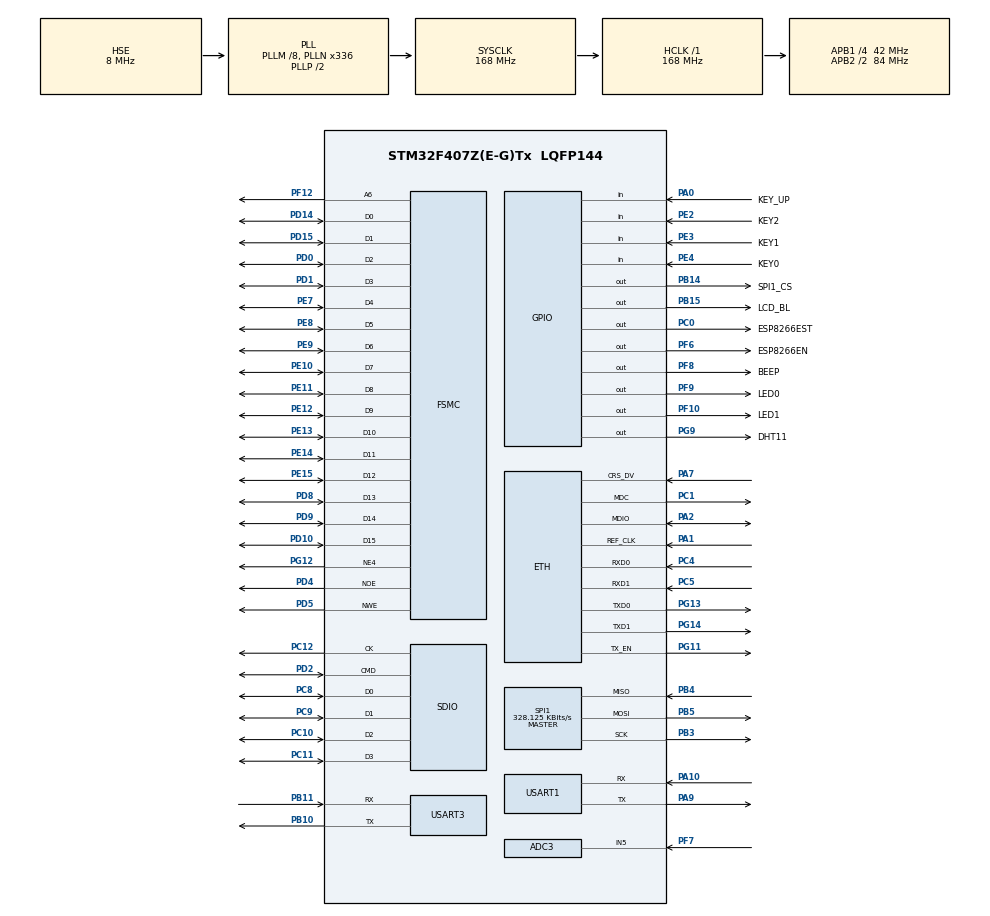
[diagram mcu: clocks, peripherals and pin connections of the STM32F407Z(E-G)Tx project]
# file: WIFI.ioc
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ADC3.Channel-6\#ChannelRegularConversion=ADC_CHANNEL_5
ADC3.NbrOfConversionFlag=1
ADC3.Rank-6\#ChannelRegularConversion=1
ADC3.SamplingTime-6\#ChannelRegularConversion=ADC_SAMPLETIME_3CYCLES
Dma.Request0=SDIO_RX
Dma.Request1=SDIO_TX
Dma.SDIO_RX.0.Direction=DMA_PERIPH_TO_MEMORY
Dma.SDIO_RX.0.FIFOMode=DMA_FIFOMODE_ENABLE
Dma.SDIO_RX.0.FIFOThreshold=DMA_FIFO_THRESHOLD_FULL
Dma.SDIO_RX.0.Instance=DMA2_Stream3
Dma.SDIO_RX.0.MemBurst=DMA_MBURST_INC4
Dma.SDIO_RX.0.MemDataAlignment=DMA_MDATAALIGN_WORD
Dma.SDIO_RX.0.MemInc=DMA_MINC_ENABLE
Dma.SDIO_RX.0.Mode=DMA_PFCTRL
Dma.SDIO_RX.0.PeriphBurst=DMA_PBURST_INC4
Dma.SDIO_RX.0.PeriphDataAlignment=DMA_PDATAALIGN_WORD
Dma.SDIO_RX.0.PeriphInc=DMA_PINC_DISABLE
Dma.SDIO_RX.0.Priority=DMA_PRIORITY_HIGH
Dma.SDIO_TX.1.Direction=DMA_MEMORY_TO_PERIPH
Dma.SDIO_TX.1.FIFOMode=DMA_FIFOMODE_ENABLE
Dma.SDIO_TX.1.FIFOThreshold=DMA_FIFO_THRESHOLD_FULL
Dma.SDIO_TX.1.Instance=DMA2_Stream6
Dma.SDIO_TX.1.MemBurst=DMA_MBURST_INC4
Dma.SDIO_TX.1.MemDataAlignment=DMA_MDATAALIGN_WORD
Dma.SDIO_TX.1.MemInc=DMA_MINC_ENABLE
Dma.SDIO_TX.1.Mode=DMA_PFCTRL
Dma.SDIO_TX.1.PeriphBurst=DMA_PBURST_INC4
Dma.SDIO_TX.1.PeriphDataAlignment=DMA_PDATAALIGN_WORD
Dma.SDIO_TX.1.PeriphInc=DMA_PINC_DISABLE
Dma.SDIO_TX.1.Priority=DMA_PRIORITY_HIGH
ETH.MediaInterface=HAL_ETH_RMII_MODE
FATFS.BSP.number=1
FATFS.USE_DMA_CODE_SD=1
FATFS._CODE_PAGE=936
FATFS._USE_LFN=2
FATFS0.BSP.STBoard=false
FATFS0.BSP.api=Unknown
FATFS0.BSP.instance=PA0-WKUP
FATFS0.BSP.ip=GPIO
FATFS0.BSP.mode=Input
FATFS0.BSP.name=Detect_SDIO
FATFS0.BSP.solution=PA0-WKUP
FSMC.AddressSetupTime1=8
FSMC.BusTurnAroundDuration1=0
FSMC.DataSetupTime1=15
FSMC.ExtendedDataSetupTime1=15
FSMC.ExtendedMode1=FSMC_EXTENDED_MODE_ENABLE
LWIP.BSP.number=1
LWIP.GATEWAY_ADDRESS=192.168.010.001
LWIP.IP_ADDRESS=192.168.010.123
LWIP.LWIP_DHCP=0
LWIP.LWIP_DNS=0
LWIP.NETMASK_ADDRESS=255.255.255.000
LWIP.Version=v2.1.2_Cube
LWIP0.BSP.STBoard=false
LWIP0.BSP.api=BSP_COMPONENT_DRIVER
LWIP0.BSP.component=LAN8742
LWIP0.BSP.instance=LAN8742
LWIP0.BSP.name=Driver_PHY
LWIP0.BSP.semaphore=S_LAN8742
LWIP0.BSP.solution=LAN8742
Mcu.Family=STM32F4
Mcu.Name=STM32F407Z(E-G)Tx
Mcu.Package=LQFP144
NVIC.DMA2_Stream3_IRQn=true\:1\:0\:true\:false\:true\:false\:true\:true
NVIC.DMA2_Stream6_IRQn=true\:1\:0\:true\:false\:true\:false\:true\:true
NVIC.ETH_IRQn=true\:3\:0\:true\:false\:true\:true\:true\:true
NVIC.ETH_WKUP_IRQn=true\:3\:0\:true\:false\:true\:true\:true\:true
NVIC.PriorityGroup=NVIC_PRIORITYGROUP_4
NVIC.SDIO_IRQn=true\:1\:0\:true\:false\:true\:true\:true\:true
NVIC.USART1_IRQn=true\:4\:0\:true\:false\:true\:true\:true\:true
NVIC.USART3_IRQn=true\:0\:0\:false\:false\:true\:true\:true\:true
PA0-WKUP.GPIO_Label=KEY_UP
PA0-WKUP.GPIO_PuPd=GPIO_PULLDOWN
PA0-WKUP.Signal=GPIO_Input
PA1.Mode=RMII
PA1.Signal=ETH_REF_CLK
PA10.Mode=Asynchronous
PA10.Signal=USART1_RX
PA13.Mode=Serial_Wire
PA13.Signal=SYS_JTMS-SWDIO
PA14.Mode=Serial_Wire
PA14.Signal=SYS_JTCK-SWCLK
PA2.Mode=RMII
PA2.Signal=ETH_MDIO
PA7.Mode=RMII
PA7.Signal=ETH_CRS_DV
PA9.Mode=Asynchronous
PA9.Signal=USART1_TX
PB10.Mode=Asynchronous
PB10.Signal=USART3_TX
PB11.Mode=Asynchronous
PB11.Signal=USART3_RX
PB14.GPIO_Label=SPI1_CS
PB14.GPIO_ModeDefaultOutputPP=GPIO_MODE_OUTPUT_PP
PB14.GPIO_Speed=GPIO_SPEED_FREQ_HIGH
PB14.PinState=GPIO_PIN_SET
PB14.Signal=GPIO_Output
PB15.GPIO_Label=LCD_BL
PB15.GPIO_Speed=GPIO_SPEED_FREQ_VERY_HIGH
PB15.PinState=GPIO_PIN_SET
PB15.Signal=GPIO_Output
PB3.Mode=Full_Duplex_Master
PB3.Signal=SPI1_SCK
PB4.Mode=Full_Duplex_Master
PB4.Signal=SPI1_MISO
PB5.Mode=Full_Duplex_Master
PB5.Signal=SPI1_MOSI
PC0.GPIO_Label=ESP8266EST
PC0.Signal=GPIO_Output
PC1.Mode=RMII
PC1.Signal=ETH_MDC
PC10.Mode=SD_4_bits_Wide_bus
PC10.Signal=SDIO_D2
PC11.Mode=SD_4_bits_Wide_bus
PC11.Signal=SDIO_D3
PC12.Mode=SD_4_bits_Wide_bus
PC12.Signal=SDIO_CK
PC14-OSC32_IN.Mode=LSE-External-Oscillator
PC14-OSC32_IN.Signal=RCC_OSC32_IN
PC15-OSC32_OUT.Mode=LSE-External-Oscillator
PC15-OSC32_OUT.Signal=RCC_OSC32_OUT
PC4.Mode=RMII
PC4.Signal=ETH_RXD0
PC5.Mode=RMII
PC5.Signal=ETH_RXD1
PC8.Mode=SD_4_bits_Wide_bus
PC8.Signal=SDIO_D0
PC9.Mode=SD_4_bits_Wide_bus
PC9.Signal=SDIO_D1
PD0.GPIO_PuPd=GPIO_NOPULL
PD0.Signal=FSMC_D2_DA2
PD1.GPIO_PuPd=GPIO_NOPULL
PD1.Signal=FSMC_D3_DA3
PD10.GPIO_PuPd=GPIO_NOPULL
PD10.Signal=FSMC_D15_DA15
PD14.GPIO_PuPd=GPIO_NOPULL
PD14.Signal=FSMC_D0_DA0
PD15.GPIO_PuPd=GPIO_NOPULL
PD15.Signal=FSMC_D1_DA1
PD2.Mode=SD_4_bits_Wide_bus
PD2.Signal=SDIO_CMD
PD4.GPIO_PuPd=GPIO_NOPULL
PD4.Signal=FSMC_NOE
PD5.GPIO_PuPd=GPIO_NOPULL
PD5.Signal=FSMC_NWE
PD8.GPIO_PuPd=GPIO_NOPULL
PD8.Signal=FSMC_D13_DA13
PD9.GPIO_PuPd=GPIO_NOPULL
PD9.Signal=FSMC_D14_DA14
PE10.GPIO_PuPd=GPIO_NOPULL
PE10.Signal=FSMC_D7_DA7
PE11.GPIO_PuPd=GPIO_NOPULL
PE11.Signal=FSMC_D8_DA8
PE12.GPIO_PuPd=GPIO_NOPULL
PE12.Signal=FSMC_D9_DA9
PE13.GPIO_PuPd=GPIO_NOPULL
PE13.Signal=FSMC_D10_DA10
PE14.GPIO_PuPd=GPIO_NOPULL
PE14.Signal=FSMC_D11_DA11
PE15.GPIO_PuPd=GPIO_NOPULL
PE15.Signal=FSMC_D12_DA12
PE2.GPIO_Label=KEY2
PE2.GPIO_PuPd=GPIO_PULLUP
PE2.Signal=GPIO_Input
PE3.GPIO_Label=KEY1
PE3.GPIO_PuPd=GPIO_PULLUP
PE3.Signal=GPIO_Input
PE4.GPIO_Label=KEY0
PE4.GPIO_PuPd=GPIO_PULLUP
PE4.Signal=GPIO_Input
PE7.GPIO_PuPd=GPIO_NOPULL
PE7.Signal=FSMC_D4_DA4
PE8.GPIO_PuPd=GPIO_NOPULL
PE8.Signal=FSMC_D5_DA5
PE9.GPIO_PuPd=GPIO_NOPULL
PE9.Signal=FSMC_D6_DA6
PF10.GPIO_Label=LED1
PF10.GPIO_PuPd=GPIO_PULLUP
PF10.GPIO_Speed=GPIO_SPEED_FREQ_MEDIUM
PF10.Signal=GPIO_Output
PF12.GPIO_PuPd=GPIO_NOPULL
PF12.Signal=FSMC_A6
PF6.GPIO_Label=ESP8266EN
PF6.GPIO_PuPd=GPIO_PULLUP
PF6.GPIO_Speed=GPIO_SPEED_FREQ_LOW
PF6.PinState=GPIO_PIN_SET
PF6.Signal=GPIO_Output
PF7.Mode=IN5
PF7.Signal=ADC3_IN5
PF8.GPIO_Label=BEEP
PF8.GPIO_PuPd=GPIO_PULLUP
PF8.GPIO_Speed=GPIO_SPEED_FREQ_HIGH
PF8.PinState=GPIO_PIN_RESET
PF8.Signal=GPIO_Output
PF9.GPIO_Label=LED0
PF9.GPIO_PuPd=GPIO_PULLUP
PF9.GPIO_Speed=GPIO_SPEED_FREQ_MEDIUM
PF9.Signal=GPIO_Output
PG11.Mode=RMII
PG11.Signal=ETH_TX_EN
PG12.GPIO_PuPd=GPIO_NOPULL
PG12.Mode=NorPsramChipSelect4_1
PG12.Signal=FSMC_NE4
PG13.Mode=RMII
PG13.Signal=ETH_TXD0
PG14.Mode=RMII
PG14.Signal=ETH_TXD1
PG9.GPIO_Label=DHT11
PG9.GPIO_PuPd=GPIO_PULLUP
PG9.GPIO_Speed=GPIO_SPEED_FREQ_HIGH
PG9.PinState=GPIO_PIN_SET
PG9.Signal=GPIO_Output
PH0-OSC_IN.Mode=HSE-External-Oscillator
PH0-OSC_IN.Signal=RCC_OSC_IN
PH1-OSC_OUT.Mode=HSE-External-Oscillator
PH1-OSC_OUT.Signal=RCC_OSC_OUT
ProjectManager.HeapSize=0x200
ProjectManager.StackSize=0x400
ProjectManager.TargetToolchain=CMake
RCC.48MHZClocksFreq_Value=48000000
RCC.AHBFreq_Value=168000000
RCC.APB1CLKDivider=RCC_HCLK_DIV4
RCC.APB1Freq_Value=42000000
RCC.APB1TimFreq_Value=84000000
RCC.APB2CLKDivider=RCC_HCLK_DIV2
RCC.APB2Freq_Value=84000000
RCC.APB2TimFreq_Value=168000000
RCC.CortexFreq_Value=168000000
RCC.HCLKFreq_Value=168000000
RCC.HSE_VALUE=8000000
RCC.HSI_VALUE=16000000
RCC.PLLM=8
RCC.PLLN=336
RCC.PLLQ=7
RCC.PLLSourceVirtual=RCC_PLLSOURCE_HSE
RCC.RCC_RTC_Clock_Source=RCC_RTCCLKSOURCE_LSI
RCC.RCC_RTC_Clock_SourceVirtual=RCC_RTCCLKSOURCE_LSE
RCC.SYSCLKFreq_VALUE=168000000
RCC.SYSCLKSource=RCC_SYSCLKSOURCE_PLLCLK
RCC.VCOOutputFreq_Value=336000000
SH.FSMC_A6.0=FSMC_A6,A6_1
SH.FSMC_D0_DA0.0=FSMC_D0,16b-d1
SH.FSMC_D10_DA10.0=FSMC_D10,16b-d1
SH.FSMC_D11_DA11.0=FSMC_D11,16b-d1
SH.FSMC_D12_DA12.0=FSMC_D12,16b-d1
SH.FSMC_D13_DA13.0=FSMC_D13,16b-d1
SH.FSMC_D14_DA14.0=FSMC_D14,16b-d1
SH.FSMC_D15_DA15.0=FSMC_D15,16b-d1
SH.FSMC_D1_DA1.0=FSMC_D1,16b-d1
SH.FSMC_D2_DA2.0=FSMC_D2,16b-d1
SH.FSMC_D3_DA3.0=FSMC_D3,16b-d1
SH.FSMC_D4_DA4.0=FSMC_D4,16b-d1
SH.FSMC_D5_DA5.0=FSMC_D5,16b-d1
SH.FSMC_D6_DA6.0=FSMC_D6,16b-d1
SH.FSMC_D7_DA7.0=FSMC_D7,16b-d1
SH.FSMC_D8_DA8.0=FSMC_D8,16b-d1
SH.FSMC_D9_DA9.0=FSMC_D9,16b-d1
SH.FSMC_NOE.0=FSMC_NOE,Lcd1
SH.FSMC_NWE.0=FSMC_NWE,Lcd1
SPI1.BaudRatePrescaler=SPI_BAUDRATEPRESCALER_256
SPI1.CLKPhase=SPI_PHASE_1EDGE
SPI1.CLKPolarity=SPI_POLARITY_LOW
SPI1.CalculateBaudRate=328.125 KBits/s
SPI1.Direction=SPI_DIRECTION_2LINES
SPI1.Mode=SPI_MODE_MASTER
SPI1.VirtualType=VM_MASTER
TIM2.AutoReloadPreload=TIM_AUTORELOAD_PRELOAD_ENABLE
TIM2.Prescaler=83
USART1.VirtualMode=VM_ASYNC
USART3.VirtualMode=VM_ASYNC
VP_FATFS_VS_SDIO.Mode=SDIO
VP_LWIP_VS_Enabled.Mode=Enabled
VP_TIM2_VS_ClockSourceINT.Mode=Internal
board=custom

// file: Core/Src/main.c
/* USER CODE BEGIN Header */
/* USER CODE END Header */
#include "main.h"
#include "fatfs.h"
#include "lwip.h"

/* USER CODE BEGIN Includes */
#include "stdio.h"
#include "string.h"
#include "stdbool.h"
#include "../../Library/led/led.h"
#include "../../Library/key/key.h"
#include "../../Library/beep/beep.h"
#include "../../Library/delay/delay.h"
#include "../../Library/tftlcd/tftlcd.h"
#include "../../Library/DHT11/dht11.h"
#include "../../Library/Light_Sensor/light_sensor.h"
#include "../../Library/mpu6050/MPU6050.h"
#include "../../Library/aliyun_iot/aliyun_iot.h"
/* USER CODE END Includes */

ADC_HandleTypeDef hadc3;

SD_HandleTypeDef hsd;
DMA_HandleTypeDef hdma_sdio_rx;
DMA_HandleTypeDef hdma_sdio_tx;

SPI_HandleTypeDef hspi1;

TIM_HandleTypeDef htim2;

UART_HandleTypeDef huart1;
UART_HandleTypeDef huart3;

SRAM_HandleTypeDef hsram1;

/* USER CODE BEGIN PV */
/* 串口/任务状态计数，用于后续调试或界面显示 */
static uint32_t g_uart_test_count = 0U;
/* MPU6050 基础驱动和 DMP 姿态解算模块的初始化状态 */
static uint8_t g_mpu_ready = 0U;
static uint8_t g_mpu_dmp_ready = 0U;
/* 非阻塞刷新定时器：主循环每 500ms 刷新一次传感器数据 */
static delay_nb_timer_t g_sensor_refresh_timer;
/* 光照、温湿度和姿态角的最新采样值，会同步给 LCD 和阿里云物联网模块 */
static uint16_t g_light_adc_value = 0U;
static float g_light_voltage_value = 0.0f;
static float g_dht_temperature_value = 0.0f;
static float g_dht_humidity_value = 0.0f;
static float g_pitch_value = 0.0f;
static float g_roll_value = 0.0f;
static float g_yaw_value = 0.0f;
/* LCD 上各字段的显示缓存，用来避免相同内容重复刷新造成闪烁 */
static char g_dht_temp_text[24] = "";
static char g_dht_humi_text[24] = "";
static char g_light_adc_text[24] = "";
static char g_light_volt_text[24] = "";
static char g_light_level_text[24] = "";
static char g_ax_text[16] = "";
static char g_ay_text[16] = "";
static char g_az_text[16] = "";
static char g_gx_text[16] = "";
static char g_gy_text[16] = "";
static char g_gz_text[16] = "";
static char g_mpu_temp_text[24] = "";
static char g_pitch_text[24] = "";
static char g_roll_text[24] = "";
static char g_yaw_text[24] = "";
static char g_status_left_text[32] = "";
static char g_status_right_text[16] = "";
/* USER CODE END PV */

void SystemClock_Config(void);
static void MX_GPIO_Init(void);
static void MX_DMA_Init(void);
static void MX_FSMC_Init(void);
static void MX_SPI1_Init(void);
static void MX_USART1_UART_Init(void);
static void MX_ADC3_Init(void);
static void MX_SDIO_SD_Init(void);
static void MX_TIM2_Init(void);
static void MX_USART3_UART_Init(void);
/* USER CODE BEGIN PFP */
static void LCD_Test_ShowWelcome(void);
static void LCD_ShowBootScreen(void);
static void LCD_UpdateBootStatus(const char *line1, const char *line2, uint16_t color);
static void LCD_Test_Run(void);
static void LCD_UpdateValueLine(uint16_t x, uint16_t y, uint16_t width, char *cache, const char *text, uint16_t color);
static void ETH_PHY_Reset(void);
/* USER CODE END PFP */

/* USER CODE BEGIN 0 */
/**
  * @brief 将当前应用层缓存的传感器数据复制给其它模块。
  * @param snapshot 输出参数，不能为 NULL。
  * @note
  * - MQTT 上报需要传感器数据，但不适合在 MQTT 发送函数中直接读 DHT11。
  * - DHT11 读取对时序敏感且可能耗时，放在主循环周期任务里更稳定。
  * - 这里做一次结构体拷贝，把最近一次 LCD_Test_Run() 采集的结果交给 MQTT。
  */
void App_GetSensorSnapshot(App_SensorSnapshot_t *snapshot)
{
  if (snapshot == NULL)
  {
    return;
  }

  snapshot->temperature = g_dht_temperature_value;
  snapshot->humidity = g_dht_humidity_value;
  snapshot->light_adc = g_light_adc_value;
  snapshot->light_voltage = g_light_voltage_value;
  snapshot->pitch = g_pitch_value;
  snapshot->roll = g_roll_value;
  snapshot->yaw = g_yaw_value;
}

static void ETH_PHY_Reset(void)
{
  printf("[ETH] PHY reset start\r\n");
  HAL_GPIO_WritePin(ETH_RESET_GPIO_Port, ETH_RESET_Pin, GPIO_PIN_RESET);
  HAL_Delay(20U);
  HAL_GPIO_WritePin(ETH_RESET_GPIO_Port, ETH_RESET_Pin, GPIO_PIN_SET);
  HAL_Delay(100U);
  printf("[ETH] PHY reset released\r\n");
}

/**
  * @brief  更新 LCD 上某一行数值文本。
  * @note   函数会按显示宽度补空格，并与缓存比较；内容没变时直接返回，
  *         这样可以减少 LCD 重绘次数，降低界面闪烁。
  */
static void LCD_UpdateValueLine(uint16_t x, uint16_t y, uint16_t width, char *cache, const char *text, uint16_t color)
{
  char padded_text[24];
  size_t max_chars = 0U;
  size_t text_len = 0U;

  if ((cache == NULL) || (text == NULL))
  {
    /* 参数无效时不刷新，避免空指针访问。 */
    return;
  }

  /* 按 8x16 字符宽度估算当前区域最多能显示多少个字符。 */
  max_chars = width / 8U;
  if (max_chars == 0U)
  {
    max_chars = 1U;
  }
  if (max_chars > (sizeof(padded_text) - 1U))
  {
    max_chars = sizeof(padded_text) - 1U;
  }

  /* 用空格填满整行，覆盖上一次较长文本留下的尾巴。 */
  memset(padded_text, ' ', max_chars);
  padded_text[max_chars] = '\0';
  text_len = strlen(text);
  if (text_len > max_chars)
  {
    text_len = max_chars;
  }
  memcpy(padded_text, text, text_len);

  if (strcmp(cache, padded_text) == 0)
  {
    /* 显示内容没有变化时跳过 LCD 写入。 */
    return;
  }

  FRONT_COLOR = color;
  LCD_ShowString(x, y, width, 20U, 16U, (uint8_t *)padded_text);
  strncpy(cache, padded_text, 23U);
  cache[23] = '\0';
}

/**
  * @brief  绘制主仪表盘的固定框架和字段标题。
  * @note   实时数据由 LCD_Test_Run() 周期刷新。
  */
static void LCD_Test_ShowWelcome(void)
{
  BACK_COLOR = WHITE;
  FRONT_COLOR = BLACK;
  LCD_Clear(WHITE);

  LCD_Fill(0U, 0U, 319U, 34U, BLUE);
  FRONT_COLOR = WHITE;
  LCD_ShowString(8U, 8U, 180U, 24U, 16U, (uint8_t *)"Sensor Dashboard");
  LCD_ShowString(220U, 8U, 90U, 24U, 16U, (uint8_t *)"500ms");

  FRONT_COLOR = BLACK;
  LCD_DrawRectangle(6U, 42U, 313U, 110U);
  LCD_DrawRectangle(6U, 118U, 313U, 196U);
  LCD_DrawRectangle(6U, 204U, 313U, 332U);
  LCD_DrawRectangle(6U, 340U, 313U, 438U);
  LCD_DrawRectangle(6U, 446U, 313U, 474U);

  FRONT_COLOR = BLUE;
  LCD_ShowString(14U, 48U, 120U, 24U, 16U, (uint8_t *)"DHT11");
  LCD_ShowString(14U, 124U, 120U, 24U, 16U, (uint8_t *)"Light Sensor");
  LCD_ShowString(14U, 210U, 150U, 24U, 16U, (uint8_t *)"MPU6050 Raw");
  LCD_ShowString(14U, 346U, 150U, 24U, 16U, (uint8_t *)"MPU6050 DMP");
  LCD_ShowString(14U, 452U, 80U, 20U, 16U, (uint8_t *)"Status");

  FRONT_COLOR = BLACK;
  LCD_ShowString(14U, 72U, 100U, 20U, 16U, (uint8_t *)"Temp:");
  LCD_ShowString(14U, 92U, 100U, 20U, 16U, (uint8_t *)"Humi:");

  LCD_ShowString(14U, 148U, 100U, 20U, 16U, (uint8_t *)"ADC:");
  LCD_ShowString(14U, 168U, 100U, 20U, 16U, (uint8_t *)"Volt:");
  LCD_ShowString(168U, 168U, 80U, 20U, 16U, (uint8_t *)"Level:");

  LCD_ShowString(14U, 236U, 40U, 20U, 16U, (uint8_t *)"AX:");
  LCD_ShowString(110U, 236U, 40U, 20U, 16U, (uint8_t *)"AY:");
  LCD_ShowString(206U, 236U, 40U, 20U, 16U, (uint8_t *)"AZ:");
  LCD_ShowString(14U, 264U, 40U, 20U, 16U, (uint8_t *)"GX:");
  LCD_ShowString(110U, 264U, 40U, 20U, 16U, (uint8_t *)"GY:");
  LCD_ShowString(206U, 264U, 40U, 20U, 16U, (uint8_t *)"GZ:");
  LCD_ShowString(14U, 292U, 60U, 20U, 16U, (uint8_t *)"Temp:");

  LCD_ShowString(14U, 372U, 60U, 20U, 16U, (uint8_t *)"Pitch:");
  LCD_ShowString(14U, 396U, 60U, 20U, 16U, (uint8_t *)"Roll:");
  LCD_ShowString(14U, 420U, 60U, 20U, 16U, (uint8_t *)"Yaw:");
}

/**
  * @brief  绘制开机初始化界面。
  */
static void LCD_ShowBootScreen(void)
{
  BACK_COLOR = WHITE;
  FRONT_COLOR = BLACK;
  LCD_Clear(WHITE);

  LCD_Fill(0U, 0U, 319U, 54U, BLUE);
  FRONT_COLOR = WHITE;
  LCD_ShowString(14U, 16U, 220U, 24U, 16U, (uint8_t *)"Sensor Dashboard");

  FRONT_COLOR = BLACK;
  LCD_DrawRectangle(18U, 90U, 302U, 230U);
  LCD_ShowString(34U, 108U, 220U, 24U, 16U, (uint8_t *)"System Booting...");
  LCD_ShowString(34U, 150U, 240U, 24U, 16U, (uint8_t *)"Init peripherals");
  LCD_ShowString(34U, 178U, 240U, 24U, 16U, (uint8_t *)"Please wait");
}

/**
  * @brief  更新开机界面的两行状态文字。
  * @param  line1 第一行状态文本，可为 NULL。
  * @param  line2 第二行状态文本，可为 NULL。
  * @param  color 文本颜色，用于区分正常状态和错误状态。
  */
static void LCD_UpdateBootStatus(const char *line1, const char *line2, uint16_t color)
{
  char text1[32];
  char text2[32];

  memset(text1, ' ', sizeof(text1) - 1U);
  memset(text2, ' ', sizeof(text2) - 1U);
  text1[sizeof(text1) - 1U] = '\0';
  text2[sizeof(text2) - 1U] = '\0';

  if (line1 != NULL)
  {
    strncpy(text1, line1, sizeof(text1) - 1U);
  }
  if (line2 != NULL)
  {
    strncpy(text2, line2, sizeof(text2) - 1U);
  }

  FRONT_COLOR = color;
  LCD_ShowString(34U, 150U, 240U, 24U, 16U, (uint8_t *)text1);
  LCD_ShowString(34U, 178U, 240U, 24U, 16U, (uint8_t *)text2);
}

/**
  * @brief  采集所有传感器数据，刷新 LCD，并把最新数据推送给阿里云 IoT 状态机。
  * @note   当前函数由主循环每 500ms 调用一次；其中 ESP8266/云端通信由
  *         AliyunIoT_Task() 在主循环中持续推进。
  */
static void LCD_Test_Run(void)
{
  char line[64];
  DHT11_Data_t dht11_sample;
  uint16_t light_adc = 0U;
  float light_voltage = 0.0f;
  LightLevel_t light_level = LIGHT_LEVEL_DARK;
  short ax = 0;
  short ay = 0;
  short az = 0;
  short gx = 0;
  short gy = 0;
  short gz = 0;
  float pitch = 0.0f;
  float roll = 0.0f;
  float yaw = 0.0f;
  AliyunIoT_SensorData_t sensor_data;

  BACK_COLOR = WHITE;
  /* 读取 DHT11 温湿度，成功时更新数值，失败时显示错误提示。 */
  if (DHT11_ReadData(&dht11_sample) == 0U)
  {
    g_dht_temperature_value = (float)dht11_sample.temp_int + ((float)dht11_sample.temp_dec / 10.0f);
    g_dht_humidity_value = (float)dht11_sample.humi_int + ((float)dht11_sample.humi_dec / 10.0f);
    snprintf(line, sizeof(line), "%u.%u C", (unsigned int)dht11_sample.temp_int, (unsigned int)dht11_sample.temp_dec);
    LCD_UpdateValueLine(120U, 72U, 180U, g_dht_temp_text, line, BLACK);
    snprintf(line, sizeof(line), "%u.%u %%RH", (unsigned int)dht11_sample.humi_int, (unsigned int)dht11_sample.humi_dec);
    LCD_UpdateValueLine(120U, 92U, 180U, g_dht_humi_text, line, BLACK);
  }
  else
  {
    LCD_UpdateValueLine(120U, 72U, 180U, g_dht_temp_text, "Read failed", RED);
    LCD_UpdateValueLine(120U, 92U, 180U, g_dht_humi_text, "--", RED);
  }

  /* 读取光敏传感器 ADC 均值，并转换成电压和亮度等级。 */
  light_adc = LightSensor_ReadADCAverage(3U);
  light_voltage = LightSensor_ConvertToVoltage(light_adc);
  light_level = LightSensor_GetLevelByADC(light_adc);
  g_light_adc_value = light_adc;
  g_light_voltage_value = light_voltage;
  snprintf(line, sizeof(line), "%u", (unsigned int)light_adc);
  LCD_UpdateValueLine(80U, 148U, 80U, g_light_adc_text, line, BLACK);
  snprintf(line, sizeof(line), "%.3f V", light_voltage);
  LCD_UpdateValueLine(80U, 168U, 78U, g_light_volt_text, line, BLACK);
  LCD_UpdateValueLine(220U, 168U, 82U, g_light_level_text, LightSensor_LevelToString(light_level), BLACK);

  /* MPU6050 基础数据：加速度、陀螺仪和芯片温度。 */
  if ((g_mpu_ready != 0U) &&
      (MPU_Get_Accelerometer(&ax, &ay, &az) == 0U) &&
      (MPU_Get_Gyroscope(&gx, &gy, &gz) == 0U))
  {
    snprintf(line, sizeof(line), "%d", ax);
    LCD_UpdateValueLine(42U, 236U, 56U, g_ax_text, line, BLACK);
    snprintf(line, sizeof(line), "%d", ay);
    LCD_UpdateValueLine(138U, 236U, 56U, g_ay_text, line, BLACK);
    snprintf(line, sizeof(line), "%d", az);
    LCD_UpdateValueLine(234U, 236U, 72U, g_az_text, line, BLACK);
    snprintf(line, sizeof(line), "%d", gx);
    LCD_UpdateValueLine(42U, 264U, 56U, g_gx_text, line, BLACK);
    snprintf(line, sizeof(line), "%d", gy);
    LCD_UpdateValueLine(138U, 264U, 56U, g_gy_text, line, BLACK);
    snprintf(line, sizeof(line), "%d", gz);
    LCD_UpdateValueLine(234U, 264U, 72U, g_gz_text, line, BLACK);
    snprintf(line, sizeof(line), "%.2f C", ((float)MPU_Get_Temperature()) / 100.0f);
    LCD_UpdateValueLine(78U, 292U, 90U, g_mpu_temp_text, line, BLACK);
  }
  else
  {
    LCD_UpdateValueLine(42U, 236U, 260U, g_ax_text, "MPU raw failed", RED);
    LCD_UpdateValueLine(138U, 236U, 56U, g_ay_text, "--", RED);
    LCD_UpdateValueLine(234U, 236U, 72U, g_az_text, "--", RED);
    LCD_UpdateValueLine(42U, 264U, 56U, g_gx_text, "--", RED);
    LCD_UpdateValueLine(138U, 264U, 56U, g_gy_text, "--", RED);
    LCD_UpdateValueLine(234U, 264U, 72U, g_gz_text, "--", RED);
    LCD_UpdateValueLine(78U, 292U, 90U, g_mpu_temp_text, "Raw failed", RED);
  }

  /* DMP 解算出的姿态角；若 DMP 未就绪，保留历史值或显示占位符。 */
  if ((g_mpu_dmp_ready != 0U) && (mpu_dmp_get_data(&pitch, &roll, &yaw) == 0U))
  {
    g_pitch_value = pitch;
    g_roll_value = roll;
    g_yaw_value = yaw;
    snprintf(line, sizeof(line), "%.2f deg", pitch);
    LCD_UpdateValueLine(78U, 372U, 130U, g_pitch_text, line, BLACK);
    snprintf(line, sizeof(line), "%.2f deg", roll);
    LCD_UpdateValueLine(78U, 396U, 130U, g_roll_text, line, BLACK);
    snprintf(line, sizeof(line), "%.2f deg", yaw);
    LCD_UpdateValueLine(78U, 420U, 130U, g_yaw_text, line, BLACK);
  }
  else
  {
    if (g_pitch_text[0] == '\0')
    {
      LCD_UpdateValueLine(78U, 372U, 130U, g_pitch_text, "--", RED);
    }
    if (g_roll_text[0] == '\0')
    {
      LCD_UpdateValueLine(78U, 396U, 130U, g_roll_text, "--", RED);
    }
    if (g_yaw_text[0] == '\0')
    {
      LCD_UpdateValueLine(78U, 420U, 130U, g_yaw_text, "--", RED);
    }
  }

  /* 将本次采样结果交给阿里云 IoT 模块，由其状态机决定何时上报。 */
  sensor_data.temperature = g_dht_temperature_value;
  sensor_data.humidity = g_dht_humidity_value;
  sensor_data.light_adc = g_light_adc_value;
  sensor_data.light_voltage = g_light_voltage_value;
  sensor_data.pitch = g_pitch_value;
  sensor_data.roll = g_roll_value;
  sensor_data.yaw = g_yaw_value;
  AliyunIoT_UpdateSensorData(&sensor_data);

  /* 在底部状态栏显示 ESP8266 最近响应、状态机步骤和 AT OK 次数。 */
  snprintf(line, sizeof(line), "ESP:%.18s", AliyunIoT_GetLastLine());
  LCD_UpdateValueLine(70U, 452U, 170U, g_status_left_text, line, BLACK);
  snprintf(line, sizeof(line), "S%u O%lu", (unsigned int)AliyunIoT_GetStep(), AliyunIoT_GetOkCount());
  LCD_UpdateValueLine(244U, 452U, 60U, g_status_right_text, line, BLACK);
}
/* USER CODE END 0 */

int main(void)
{

  /* MCU Configuration--------------------------------------------------------*/

  /* Reset of all peripherals, Initializes the Flash interface and the Systick. */
  HAL_Init();

  /* Configure the system clock */
  SystemClock_Config();

  /* Initialize all configured peripherals */
  MX_GPIO_Init();
  MX_DMA_Init();
  MX_FSMC_Init();
  MX_SPI1_Init();
  MX_USART1_UART_Init();
  MX_ADC3_Init();
  MX_SDIO_SD_Init();
  MX_FATFS_Init();
  MX_TIM2_Init();
  MX_USART3_UART_Init();
  /* 初始化板级外设驱动：LED、按键、蜂鸣器和延时模块 */
  LED_Init();
  Key_Init();
  BEEP_Init();
  delay_init();
  delay_nb_init();
  /* 初始化 LCD，并在传感器准备期间显示开机状态 */
  TFTLCD_Init();
  LCD_ShowBootScreen();
  LCD_UpdateBootStatus("LCD init done", "Init sensors", BLACK);
  /* 拉高 ESP8266 复位/使能相关引脚，使模块进入工作状态 */
  HAL_GPIO_WritePin(ESP8266EST_GPIO_Port, ESP8266EST_Pin, GPIO_PIN_SET);
  /* 初始化本地传感器：DHT11 温湿度和光敏 ADC */
  DHT11_Init();
  LightSensor_Init();
  LCD_UpdateBootStatus("Sensor init done", "Init ESP8266", BLACK);
  /* USART3 连接 ESP8266，阿里云 IoT 模块通过状态机发送 AT 指令 */
  AliyunIoT_Init(&huart3);
  LCD_UpdateBootStatus("ESP8266 init done", "Init MPU6050", BLACK);
  /* 初始化 MPU6050；DMP 依赖基础初始化成功后再加载 */
  g_mpu_ready = (MPU_Init() == 0U) ? 1U : 0U;
  LCD_UpdateBootStatus((g_mpu_ready != 0U) ? "MPU6050 init ok" : "MPU6050 init fail",
                       "Init DMP",
                       (g_mpu_ready != 0U) ? BLACK : RED);
  g_mpu_dmp_ready = ((g_mpu_ready != 0U) && (mpu_dmp_init() == 0U)) ? 1U : 0U;
  LCD_UpdateBootStatus((g_mpu_dmp_ready != 0U) ? "DMP init ok" : "DMP init fail",
                       "Load dashboard",
                       (g_mpu_dmp_ready != 0U) ? BLACK : RED);
  /* 绘制仪表盘并立即刷新一次数据，之后由非阻塞定时器周期刷新 */
  LCD_Test_ShowWelcome();
  LCD_Test_Run();

  /* 最后启动以太网：避免 LCD、MPU、传感器初始化阶段再次改动 GPIO/时钟后影响 ETH 接收。 */
  ETH_PHY_Reset();
  MX_LWIP_Init();

  delay_nb_start_ms(&g_sensor_refresh_timer, 500U);

  printf("\r\n===== Sensor Dashboard =====\r\n");
  printf("Single page refresh interval: 500 ms\r\n");
  printf("MPU base init = %u, DMP init = %u\r\n", (unsigned int)g_mpu_ready, (unsigned int)g_mpu_dmp_ready);
  printf("ESP8266 phase-1 IoT flow via USART3 started\r\n");
  printf("=============================\r\n");
  /* USER CODE END 2 */

  /* Infinite loop */
  /* USER CODE BEGIN WHILE */
  while (1)
  {
    if (delay_nb_is_expired(&g_sensor_refresh_timer) == 1U)
    {
      g_uart_test_count++;
      LCD_Test_Run();
      delay_nb_start_ms(&g_sensor_refresh_timer, 500U);
    }

    // AliyunIoT_Task();
    /* USER CODE END WHILE */

    /* USER CODE BEGIN 3 */
    MX_LWIP_Process();
  }
  /* USER CODE END 3 */
}

void SystemClock_Config(void)
{
  RCC_OscInitTypeDef RCC_OscInitStruct = {0};
  RCC_ClkInitTypeDef RCC_ClkInitStruct = {0};

  /** Configure the main internal regulator output voltage
  */
  __HAL_RCC_PWR_CLK_ENABLE();
  __HAL_PWR_VOLTAGESCALING_CONFIG(PWR_REGULATOR_VOLTAGE_SCALE1);

  /** Initializes the RCC Oscillators according to the specified parameters
  * in the RCC_OscInitTypeDef structure.
  */
  RCC_OscInitStruct.OscillatorType = RCC_OSCILLATORTYPE_HSE;
  RCC_OscInitStruct.HSEState = RCC_HSE_ON;
  RCC_OscInitStruct.PLL.PLLState = RCC_PLL_ON;
  RCC_OscInitStruct.PLL.PLLSource = RCC_PLLSOURCE_HSE;
  RCC_OscInitStruct.PLL.PLLM = 8;
  RCC_OscInitStruct.PLL.PLLN = 336;
  RCC_OscInitStruct.PLL.PLLP = RCC_PLLP_DIV2;
  RCC_OscInitStruct.PLL.PLLQ = 7;
  if (HAL_RCC_OscConfig(&RCC_OscInitStruct) != HAL_OK)
  {
    Error_Handler();
  }

  /** Initializes the CPU, AHB and APB buses clocks
  */
  RCC_ClkInitStruct.ClockType = RCC_CLOCKTYPE_HCLK|RCC_CLOCKTYPE_SYSCLK
                              |RCC_CLOCKTYPE_PCLK1|RCC_CLOCKTYPE_PCLK2;
  RCC_ClkInitStruct.SYSCLKSource = RCC_SYSCLKSOURCE_PLLCLK;
  RCC_ClkInitStruct.AHBCLKDivider = RCC_SYSCLK_DIV1;
  RCC_ClkInitStruct.APB1CLKDivider = RCC_HCLK_DIV4;
  RCC_ClkInitStruct.APB2CLKDivider = RCC_HCLK_DIV2;

  if (HAL_RCC_ClockConfig(&RCC_ClkInitStruct, FLASH_LATENCY_5) != HAL_OK)
  {
    Error_Handler();
  }
}

static void MX_ADC3_Init(void)
{

  ADC_ChannelConfTypeDef sConfig = {0};

  /** Configure the global features of the ADC (Clock, Resolution, Data Alignment and number of conversion)
  */
  hadc3.Instance = ADC3;
  hadc3.Init.ClockPrescaler = ADC_CLOCK_SYNC_PCLK_DIV4;
  hadc3.Init.Resolution = ADC_RESOLUTION_12B;
  hadc3.Init.ScanConvMode = DISABLE;
  hadc3.Init.ContinuousConvMode = DISABLE;
  hadc3.Init.DiscontinuousConvMode = DISABLE;
  hadc3.Init.ExternalTrigConvEdge = ADC_EXTERNALTRIGCONVEDGE_NONE;
  hadc3.Init.ExternalTrigConv = ADC_SOFTWARE_START;
  hadc3.Init.DataAlign = ADC_DATAALIGN_RIGHT;
  hadc3.Init.NbrOfConversion = 1;
  hadc3.Init.DMAContinuousRequests = DISABLE;
  hadc3.Init.EOCSelection = ADC_EOC_SINGLE_CONV;
  if (HAL_ADC_Init(&hadc3) != HAL_OK)
  {
    Error_Handler();
  }

  /** Configure for the selected ADC regular channel its corresponding rank in the sequencer and its sample time.
  */
  sConfig.Channel = ADC_CHANNEL_5;
  sConfig.Rank = 1;
  sConfig.SamplingTime = ADC_SAMPLETIME_3CYCLES;
  if (HAL_ADC_ConfigChannel(&hadc3, &sConfig) != HAL_OK)
  {
    Error_Handler();
  }

}

static void MX_SDIO_SD_Init(void)
{

  hsd.Instance = SDIO;
  hsd.Init.ClockEdge = SDIO_CLOCK_EDGE_RISING;
  hsd.Init.ClockBypass = SDIO_CLOCK_BYPASS_DISABLE;
  hsd.Init.ClockPowerSave = SDIO_CLOCK_POWER_SAVE_DISABLE;
  hsd.Init.BusWide = SDIO_BUS_WIDE_1B;
  hsd.Init.HardwareFlowControl = SDIO_HARDWARE_FLOW_CONTROL_DISABLE;
  hsd.Init.ClockDiv = 0;

}

static void MX_SPI1_Init(void)
{

  /* SPI1 parameter configuration*/
  hspi1.Instance = SPI1;
  hspi1.Init.Mode = SPI_MODE_MASTER;
  hspi1.Init.Direction = SPI_DIRECTION_2LINES;
  hspi1.Init.DataSize = SPI_DATASIZE_8BIT;
  hspi1.Init.CLKPolarity = SPI_POLARITY_LOW;
  hspi1.Init.CLKPhase = SPI_PHASE_1EDGE;
  hspi1.Init.NSS = SPI_NSS_SOFT;
  hspi1.Init.BaudRatePrescaler = SPI_BAUDRATEPRESCALER_256;
  hspi1.Init.FirstBit = SPI_FIRSTBIT_MSB;
  hspi1.Init.TIMode = SPI_TIMODE_DISABLE;
  hspi1.Init.CRCCalculation = SPI_CRCCALCULATION_DISABLE;
  hspi1.Init.CRCPolynomial = 10;
  if (HAL_SPI_Init(&hspi1) != HAL_OK)
  {
    Error_Handler();
  }

}

static void MX_TIM2_Init(void)
{

  TIM_ClockConfigTypeDef sClockSourceConfig = {0};
  TIM_MasterConfigTypeDef sMasterConfig = {0};

  htim2.Instance = TIM2;
  htim2.Init.Prescaler = 83;
  htim2.Init.CounterMode = TIM_COUNTERMODE_UP;
  htim2.Init.Period = 4294967295;
  htim2.Init.ClockDivision = TIM_CLOCKDIVISION_DIV1;
  htim2.Init.AutoReloadPreload = TIM_AUTORELOAD_PRELOAD_ENABLE;
  if (HAL_TIM_Base_Init(&htim2) != HAL_OK)
  {
    Error_Handler();
  }
  sClockSourceConfig.ClockSource = TIM_CLOCKSOURCE_INTERNAL;
  if (HAL_TIM_ConfigClockSource(&htim2, &sClockSourceConfig) != HAL_OK)
  {
    Error_Handler();
  }
  sMasterConfig.MasterOutputTrigger = TIM_TRGO_RESET;
  sMasterConfig.MasterSlaveMode = TIM_MASTERSLAVEMODE_DISABLE;
  if (HAL_TIMEx_MasterConfigSynchronization(&htim2, &sMasterConfig) != HAL_OK)
  {
    Error_Handler();
  }

}

static void MX_USART1_UART_Init(void)
{

  huart1.Instance = USART1;
  huart1.Init.BaudRate = 115200;
  huart1.Init.WordLength = UART_WORDLENGTH_8B;
  huart1.Init.StopBits = UART_STOPBITS_1;
  huart1.Init.Parity = UART_PARITY_NONE;
  huart1.Init.Mode = UART_MODE_TX_RX;
  huart1.Init.HwFlowCtl = UART_HWCONTROL_NONE;
  huart1.Init.OverSampling = UART_OVERSAMPLING_16;
  if (HAL_UART_Init(&huart1) != HAL_OK)
  {
    Error_Handler();
  }

}

static void MX_USART3_UART_Init(void)
{

  huart3.Instance = USART3;
  huart3.Init.BaudRate = 115200;
  huart3.Init.WordLength = UART_WORDLENGTH_8B;
  huart3.Init.StopBits = UART_STOPBITS_1;
  huart3.Init.Parity = UART_PARITY_NONE;
  huart3.Init.Mode = UART_MODE_TX_RX;
  huart3.Init.HwFlowCtl = UART_HWCONTROL_NONE;
  huart3.Init.OverSampling = UART_OVERSAMPLING_16;
  if (HAL_UART_Init(&huart3) != HAL_OK)
  {
    Error_Handler();
  }

}

static void MX_DMA_Init(void)
{

  /* DMA controller clock enable */
  __HAL_RCC_DMA2_CLK_ENABLE();

  /* DMA interrupt init */
  /* DMA2_Stream3_IRQn interrupt configuration */
  HAL_NVIC_SetPriority(DMA2_Stream3_IRQn, 1, 0);
  HAL_NVIC_EnableIRQ(DMA2_Stream3_IRQn);
  /* DMA2_Stream6_IRQn interrupt configuration */
  HAL_NVIC_SetPriority(DMA2_Stream6_IRQn, 1, 0);
  HAL_NVIC_EnableIRQ(DMA2_Stream6_IRQn);

}

static void MX_GPIO_Init(void)
{
  GPIO_InitTypeDef GPIO_InitStruct = {0};

  /* GPIO Ports Clock Enable */
  __HAL_RCC_GPIOE_CLK_ENABLE();
  __HAL_RCC_GPIOC_CLK_ENABLE();
  __HAL_RCC_GPIOF_CLK_ENABLE();
  __HAL_RCC_GPIOH_CLK_ENABLE();
  __HAL_RCC_GPIOA_CLK_ENABLE();
  __HAL_RCC_GPIOB_CLK_ENABLE();
  __HAL_RCC_GPIOD_CLK_ENABLE();
  __HAL_RCC_GPIOG_CLK_ENABLE();

  /*Configure GPIO pin Output Level */
  HAL_GPIO_WritePin(ESP8266EN_GPIO_Port, ESP8266EN_Pin, GPIO_PIN_SET);

  /*Configure GPIO pin Output Level */
  HAL_GPIO_WritePin(GPIOF, BEEP_Pin|LED0_Pin|LED1_Pin, GPIO_PIN_RESET);

  /*Configure GPIO pin Output Level */
  HAL_GPIO_WritePin(ESP8266EST_GPIO_Port, ESP8266EST_Pin, GPIO_PIN_RESET);

  /*Configure GPIO pin Output Level */
  HAL_GPIO_WritePin(GPIOB, SPI1_CS_Pin|LCD_BL_Pin, GPIO_PIN_SET);

  /*Configure GPIO pin Output Level */
  HAL_GPIO_WritePin(DHT11_GPIO_Port, DHT11_Pin, GPIO_PIN_SET);

  /*Configure GPIO pin Output Level */
  HAL_GPIO_WritePin(ETH_RESET_GPIO_Port, ETH_RESET_Pin, GPIO_PIN_SET);

  /*Configure GPIO pins : KEY2_Pin KEY1_Pin KEY0_Pin */
  GPIO_InitStruct.Pin = KEY2_Pin|KEY1_Pin|KEY0_Pin;
  GPIO_InitStruct.Mode = GPIO_MODE_INPUT;
  GPIO_InitStruct.Pull = GPIO_PULLUP;
  HAL_GPIO_Init(GPIOE, &GPIO_InitStruct);

  /*Configure GPIO pin : ESP8266EN_Pin */
  GPIO_InitStruct.Pin = ESP8266EN_Pin;
  GPIO_InitStruct.Mode = GPIO_MODE_OUTPUT_PP;
  GPIO_InitStruct.Pull = GPIO_PULLUP;
  GPIO_InitStruct.Speed = GPIO_SPEED_FREQ_LOW;
  HAL_GPIO_Init(ESP8266EN_GPIO_Port, &GPIO_InitStruct);

  /*Configure GPIO pin : BEEP_Pin */
  GPIO_InitStruct.Pin = BEEP_Pin;
  GPIO_InitStruct.Mode = GPIO_MODE_OUTPUT_PP;
  GPIO_InitStruct.Pull = GPIO_PULLUP;
  GPIO_InitStruct.Speed = GPIO_SPEED_FREQ_HIGH;
  HAL_GPIO_Init(BEEP_GPIO_Port, &GPIO_InitStruct);

  /*Configure GPIO pins : LED0_Pin LED1_Pin */
  GPIO_InitStruct.Pin = LED0_Pin|LED1_Pin;
  GPIO_InitStruct.Mode = GPIO_MODE_OUTPUT_PP;
  GPIO_InitStruct.Pull = GPIO_PULLUP;
  GPIO_InitStruct.Speed = GPIO_SPEED_FREQ_MEDIUM;
  HAL_GPIO_Init(GPIOF, &GPIO_InitStruct);

  /*Configure GPIO pin : ESP8266EST_Pin */
  GPIO_InitStruct.Pin = ESP8266EST_Pin;
  GPIO_InitStruct.Mode = GPIO_MODE_OUTPUT_PP;
  GPIO_InitStruct.Pull = GPIO_NOPULL;
  GPIO_InitStruct.Speed = GPIO_SPEED_FREQ_LOW;
  HAL_GPIO_Init(ESP8266EST_GPIO_Port, &GPIO_InitStruct);

  /*Configure GPIO pin : KEY_UP_Pin */
  GPIO_InitStruct.Pin = KEY_UP_Pin;
  GPIO_InitStruct.Mode = GPIO_MODE_INPUT;
  GPIO_InitStruct.Pull = GPIO_PULLDOWN;
  HAL_GPIO_Init(KEY_UP_GPIO_Port, &GPIO_InitStruct);

  /*Configure GPIO pin : SPI1_CS_Pin */
  GPIO_InitStruct.Pin = SPI1_CS_Pin;
  GPIO_InitStruct.Mode = GPIO_MODE_OUTPUT_PP;
  GPIO_InitStruct.Pull = GPIO_NOPULL;
  GPIO_InitStruct.Speed = GPIO_SPEED_FREQ_HIGH;
  HAL_GPIO_Init(SPI1_CS_GPIO_Port, &GPIO_InitStruct);

  /*Configure GPIO pin : LCD_BL_Pin */
  GPIO_InitStruct.Pin = LCD_BL_Pin;
  GPIO_InitStruct.Mode = GPIO_MODE_OUTPUT_PP;
  GPIO_InitStruct.Pull = GPIO_NOPULL;
  GPIO_InitStruct.Speed = GPIO_SPEED_FREQ_VERY_HIGH;
  HAL_GPIO_Init(LCD_BL_GPIO_Port, &GPIO_InitStruct);

  /*Configure GPIO pin : DHT11_Pin */
  GPIO_InitStruct.Pin = DHT11_Pin;
  GPIO_InitStruct.Mode = GPIO_MODE_OUTPUT_PP;
  GPIO_InitStruct.Pull = GPIO_PULLUP;
  GPIO_InitStruct.Speed = GPIO_SPEED_FREQ_HIGH;
  HAL_GPIO_Init(DHT11_GPIO_Port, &GPIO_InitStruct);

  /*Configure GPIO pin : ETH_RESET_Pin */
  GPIO_InitStruct.Pin = ETH_RESET_Pin;
  GPIO_InitStruct.Mode = GPIO_MODE_OUTPUT_PP;
  GPIO_InitStruct.Pull = GPIO_PULLUP;
  GPIO_InitStruct.Speed = GPIO_SPEED_FREQ_LOW;
  HAL_GPIO_Init(ETH_RESET_GPIO_Port, &GPIO_InitStruct);

}

/* FSMC initialization function */
static void MX_FSMC_Init(void)
{

  FSMC_NORSRAM_TimingTypeDef Timing = {0};
  FSMC_NORSRAM_TimingTypeDef ExtTiming = {0};

  /** Perform the SRAM1 memory initialization sequence
  */
  hsram1.Instance = FSMC_NORSRAM_DEVICE;
  hsram1.Extended = FSMC_NORSRAM_EXTENDED_DEVICE;
  /* hsram1.Init */
  hsram1.Init.NSBank = FSMC_NORSRAM_BANK4;
  hsram1.Init.DataAddressMux = FSMC_DATA_ADDRESS_MUX_DISABLE;
  hsram1.Init.MemoryType = FSMC_MEMORY_TYPE_SRAM;
  hsram1.Init.MemoryDataWidth = FSMC_NORSRAM_MEM_BUS_WIDTH_16;
  hsram1.Init.BurstAccessMode = FSMC_BURST_ACCESS_MODE_DISABLE;
  hsram1.Init.WaitSignalPolarity = FSMC_WAIT_SIGNAL_POLARITY_LOW;
  hsram1.Init.WrapMode = FSMC_WRAP_MODE_DISABLE;
  hsram1.Init.WaitSignalActive = FSMC_WAIT_TIMING_BEFORE_WS;
  hsram1.Init.WriteOperation = FSMC_WRITE_OPERATION_ENABLE;
  hsram1.Init.WaitSignal = FSMC_WAIT_SIGNAL_DISABLE;
  hsram1.Init.ExtendedMode = FSMC_EXTENDED_MODE_ENABLE;
  hsram1.Init.AsynchronousWait = FSMC_ASYNCHRONOUS_WAIT_DISABLE;
  hsram1.Init.WriteBurst = FSMC_WRITE_BURST_DISABLE;
  hsram1.Init.PageSize = FSMC_PAGE_SIZE_NONE;
  /* Timing */
  Timing.AddressSetupTime = 8;
  Timing.AddressHoldTime = 15;
  Timing.DataSetupTime = 15;
  Timing.BusTurnAroundDuration = 0;
  Timing.CLKDivision = 16;
  Timing.DataLatency = 17;
  Timing.AccessMode = FSMC_ACCESS_MODE_A;
  /* ExtTiming */
  ExtTiming.AddressSetupTime = 15;
  ExtTiming.AddressHoldTime = 15;
  ExtTiming.DataSetupTime = 15;
  ExtTiming.BusTurnAroundDuration = 15;
  ExtTiming.CLKDivision = 16;
  ExtTiming.DataLatency = 17;
  ExtTiming.AccessMode = FSMC_ACCESS_MODE_A;

  if (HAL_SRAM_Init(&hsram1, &Timing, &ExtTiming) != HAL_OK)
  {
    Error_Handler( );
  }

}

  /* 串口接收完成后交给阿里云 IoT 模块处理，当前主要关注 USART3/ESP8266 */
void HAL_UART_RxCpltCallback(UART_HandleTypeDef *huart)
{
  AliyunIoT_RxCpltCallback(huart);
}
/* USER CODE END 4 */

void Error_Handler(void)
{
}
